# UFS0_SYSCFG_SS_CFG register map
Vendor: Texas Instruments
Peripheral module from a debugger description file (folder J7ES).
Registers are 32-bit, read-only, reset 0x68556100 unless marked. A register's access mark holds for its fields unless they carry their own. Offsets are as the file gives them; lines under a group give offsets from that group; [hi:lo] are bit positions; {n}, {i} and the like mark numbered series; 'fields as' and 'values as' point back to an identical list; <NAME> marks a mode.

## UFS0_SYSCFG_SS_CFG
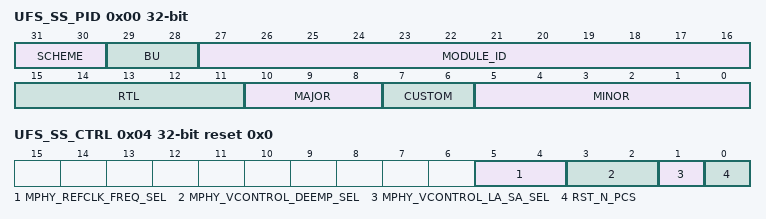
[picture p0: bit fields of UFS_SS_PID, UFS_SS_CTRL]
0x00 UFS_SS_PID — The Revision Register contains the major and minor revisions for the module.
  [31:30] SCHEME
  [29:28] BU — Business Unit: 2h = Processors
  [27:16] MODULE_ID
  [15:11] RTL — RTL Revision
  [10:8] MAJOR — Major Revision
  [7:6] CUSTOM
  [5:0] MINOR — Minor Revision
0x04 UFS_SS_CTRL access per field reset 0x0 — The Control Register contains general control bits for the module.
  [5:4] MPHY_REFCLK_FREQ_SEL rw — Reference Clock Frequency Selection 0h = 19.2 MHz 1h = 26 MHz 2h = Reserved 3h = Reserved
  [3:2] MPHY_VCONTROL_DEEMP_SEL rw — M-PHY De-Emphasis Select 0h = No De-Emphasis 1h = De-Emphasis
  [1] MPHY_VCONTROL_LA_SA_SEL rw — M-PHY Amplitude Select 0h = Small Amplitude 1h = Large Amplitude
  [0] RST_N_PCS rw — Active Low Reset to UFS Slave Device
